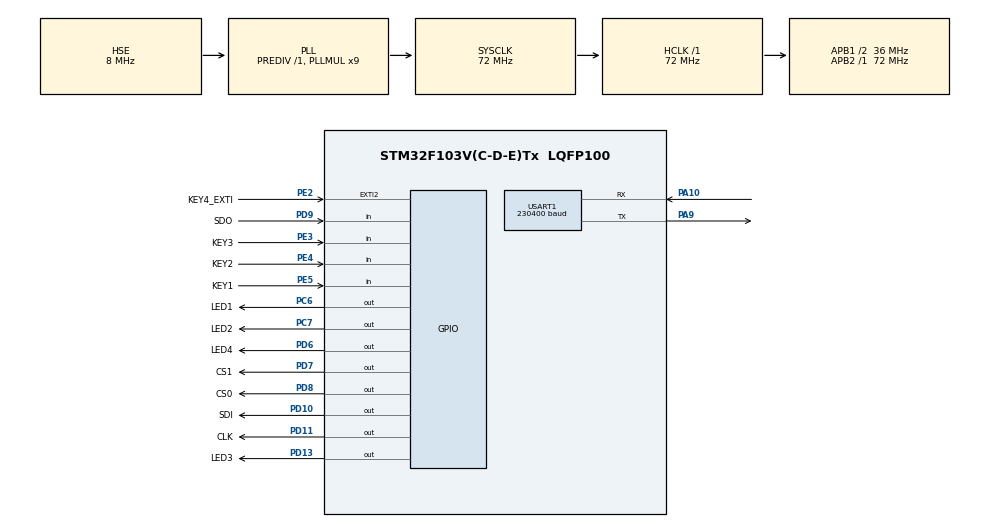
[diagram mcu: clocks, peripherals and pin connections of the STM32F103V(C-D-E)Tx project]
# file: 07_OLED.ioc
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Mcu.Family=STM32F1
Mcu.Name=STM32F103V(C-D-E)Tx
Mcu.Package=LQFP100
NVIC.EXTI2_IRQn=true\:2\:0\:true\:false\:true\:true
NVIC.PriorityGroup=NVIC_PRIORITYGROUP_4
OSC_IN.Mode=HSE-External-Oscillator
OSC_IN.Signal=RCC_OSC_IN
OSC_OUT.Mode=HSE-External-Oscillator
OSC_OUT.Signal=RCC_OSC_OUT
PA10.Mode=Asynchronous
PA10.Signal=USART1_RX
PA9.Mode=Asynchronous
PA9.Signal=USART1_TX
PC6.GPIO_Label=LED1
PC6.GPIO_Speed=GPIO_SPEED_FREQ_LOW
PC6.Signal=GPIO_Output
PC7.GPIO_Label=LED2
PC7.GPIO_ModeDefaultOutputPP=GPIO_MODE_OUTPUT_PP
PC7.GPIO_Speed=GPIO_SPEED_FREQ_LOW
PC7.Signal=GPIO_Output
PD10.GPIO_Label=SDI
PD10.GPIO_Speed=GPIO_SPEED_FREQ_HIGH
PD10.PinState=GPIO_PIN_RESET
PD10.Signal=GPIO_Output
PD11.GPIO_Label=CLK
PD11.GPIO_Speed=GPIO_SPEED_FREQ_HIGH
PD11.Signal=GPIO_Output
PD13.GPIO_Label=LED3
PD13.Signal=GPIO_Output
PD6.GPIO_Label=LED4
PD6.Signal=GPIO_Output
PD7.GPIO_Label=CS1
PD7.GPIO_Speed=GPIO_SPEED_FREQ_HIGH
PD7.PinState=GPIO_PIN_RESET
PD7.Signal=GPIO_Output
PD8.GPIO_Label=CS0
PD8.GPIO_Speed=GPIO_SPEED_FREQ_HIGH
PD8.PinState=GPIO_PIN_RESET
PD8.Signal=GPIO_Output
PD9.GPIO_Label=SDO
PD9.GPIO_PuPd=GPIO_PULLUP
PD9.Signal=GPIO_Input
PE2.GPIO_Label=KEY4_EXTI
PE2.GPIO_ModeDefaultEXTI=GPIO_MODE_IT_FALLING
PE2.Signal=GPXTI2
PE3.GPIO_Label=KEY3
PE3.Signal=GPIO_Input
PE4.GPIO_Label=KEY2
PE4.Signal=GPIO_Input
PE5.GPIO_Label=KEY1
PE5.Signal=GPIO_Input
ProjectManager.HeapSize=0x200
ProjectManager.StackSize=0x400
ProjectManager.TargetToolchain=SW4STM32
RCC.AHBFreq_Value=72000000
RCC.APB1CLKDivider=RCC_HCLK_DIV2
RCC.APB1Freq_Value=36000000
RCC.APB1TimFreq_Value=72000000
RCC.APB2Freq_Value=72000000
RCC.APB2TimFreq_Value=72000000
RCC.HCLKFreq_Value=72000000
RCC.PLLMUL=RCC_PLL_MUL9
RCC.PLLSourceVirtual=RCC_PLLSOURCE_HSE
RCC.SYSCLKFreq_VALUE=72000000
RCC.SYSCLKSource=RCC_SYSCLKSOURCE_PLLCLK
RCC.USBFreq_Value=72000000
USART1.BaudRate=230400
USART1.VirtualMode=VM_ASYNC
VP_SYS_VS_ND.Mode=No_Debug
board=custom

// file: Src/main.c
/* USER CODE BEGIN Header */
/**
  ******************************************************************************
  * @file           : main.c
  * @brief          : Main program body
  ******************************************************************************
  ** This notice applies to any and all portions of this file
  * that are not between comment pairs USER CODE BEGIN and
  * USER CODE END. Other portions of this file, whether
  * inserted by the user or by software development tools
  * are owned by their respective copyright owners.
  *
  * COPYRIGHT(c) 2019 STMicroelectronics
  *
  * Redistribution and use in source and binary forms, with or without modification,
  * are permitted provided that the following conditions are met:
  *   1. Redistributions of source code must retain the above copyright notice,
  *      this list of conditions and the following disclaimer.
  *   2. Redistributions in binary form must reproduce the above copyright notice,
  *      this list of conditions and the following disclaimer in the documentation
  *      and/or other materials provided with the distribution.
  *   3. Neither the name of STMicroelectronics nor the names of its contributors
  *      may be used to endorse or promote products derived from this software
  *      without specific prior written permission.
  *
  * THIS SOFTWARE IS PROVIDED BY THE COPYRIGHT HOLDERS AND CONTRIBUTORS "AS IS"
  * AND ANY EXPRESS OR IMPLIED WARRANTIES, INCLUDING, BUT NOT LIMITED TO, THE
  * IMPLIED WARRANTIES OF MERCHANTABILITY AND FITNESS FOR A PARTICULAR PURPOSE ARE
  * DISCLAIMED. IN NO EVENT SHALL THE COPYRIGHT HOLDER OR CONTRIBUTORS BE LIABLE
  * FOR ANY DIRECT, INDIRECT, INCIDENTAL, SPECIAL, EXEMPLARY, OR CONSEQUENTIAL
  * DAMAGES (INCLUDING, BUT NOT LIMITED TO, PROCUREMENT OF SUBSTITUTE GOODS OR
  * SERVICES; LOSS OF USE, DATA, OR PROFITS; OR BUSINESS INTERRUPTION) HOWEVER
  * CAUSED AND ON ANY THEORY OF LIABILITY, WHETHER IN CONTRACT, STRICT LIABILITY,
  * OR TORT (INCLUDING NEGLIGENCE OR OTHERWISE) ARISING IN ANY WAY OUT OF THE USE
  * OF THIS SOFTWARE, EVEN IF ADVISED OF THE POSSIBILITY OF SUCH DAMAGE.
  *
  ******************************************************************************
  */
/* USER CODE END Header */

#include "main.h"
#include "usart.h"
#include "gpio.h"

/* USER CODE BEGIN Includes */
#include "oled.h"
/* USER CODE END Includes */

/* USER CODE BEGIN PD */
#define DEBUG
/* USER CODE END PD */

void SystemClock_Config(void);

int main(void)
{
  /* USER CODE BEGIN 1 */
  unsigned int i;
  /* USER CODE END 1 */

  /* MCU Configuration--------------------------------------------------------*/

  /* Reset of all peripherals, Initializes the Flash interface and the Systick. */
  HAL_Init();

  /* Configure the system clock */
  SystemClock_Config();

  /* Initialize all configured peripherals */
  MX_GPIO_Init();
  MX_USART1_UART_Init();
  OLED_Init();
//  DispStr_GB2312(20,0,"込込");
  OLED_DispStr(0,0, (uint8_t*)"Size 8X6 Test", FONT_8X6);
  OLED_DispStr(0,6, (uint8_t*)"Size 16X8 Test", FONT_16X8);
  /* Infinite loop */
  while (1)
  {
    /* USER CODE BEGIN 3 */
    #ifdef DEBUG
      HAL_GPIO_TogglePin(LED1_GPIO_Port, LED1_Pin);
      for(i=0; i<500; i++)
      {
	    Delay_Us(1000);
      }
    #else
      asm("NOP");
    #endif
  }
  /* USER CODE END 3 */
}

void SystemClock_Config(void)
{
  RCC_OscInitTypeDef RCC_OscInitStruct = {0};
  RCC_ClkInitTypeDef RCC_ClkInitStruct = {0};

  /**Initializes the CPU, AHB and APB busses clocks
  */
  RCC_OscInitStruct.OscillatorType = RCC_OSCILLATORTYPE_HSE;
  RCC_OscInitStruct.HSEState = RCC_HSE_ON;
  RCC_OscInitStruct.HSEPredivValue = RCC_HSE_PREDIV_DIV1;
  RCC_OscInitStruct.HSIState = RCC_HSI_ON;
  RCC_OscInitStruct.PLL.PLLState = RCC_PLL_ON;
  RCC_OscInitStruct.PLL.PLLSource = RCC_PLLSOURCE_HSE;
  RCC_OscInitStruct.PLL.PLLMUL = RCC_PLL_MUL9;
  if (HAL_RCC_OscConfig(&RCC_OscInitStruct) != HAL_OK)
  {
    Error_Handler();
  }
  /**Initializes the CPU, AHB and APB busses clocks
  */
  RCC_ClkInitStruct.ClockType = RCC_CLOCKTYPE_HCLK|RCC_CLOCKTYPE_SYSCLK
                              |RCC_CLOCKTYPE_PCLK1|RCC_CLOCKTYPE_PCLK2;
  RCC_ClkInitStruct.SYSCLKSource = RCC_SYSCLKSOURCE_PLLCLK;
  RCC_ClkInitStruct.AHBCLKDivider = RCC_SYSCLK_DIV1;
  RCC_ClkInitStruct.APB1CLKDivider = RCC_HCLK_DIV2;
  RCC_ClkInitStruct.APB2CLKDivider = RCC_HCLK_DIV1;

  if (HAL_RCC_ClockConfig(&RCC_ClkInitStruct, FLASH_LATENCY_2) != HAL_OK)
  {
    Error_Handler();
  }
}

void Error_Handler(void)
{
}

/************************ (C) COPYRIGHT STMicroelectronics *****END OF FILE****/
